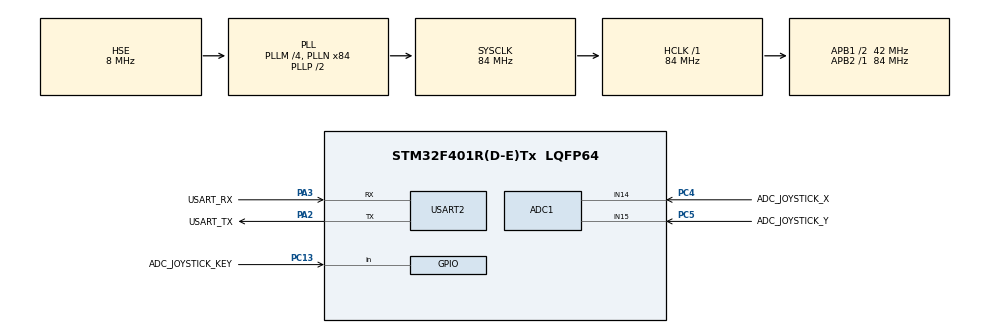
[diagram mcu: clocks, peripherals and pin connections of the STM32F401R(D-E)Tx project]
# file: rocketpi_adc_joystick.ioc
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ADC1.Channel-0\#ChannelRegularConversion=ADC_CHANNEL_14
ADC1.Channel-1\#ChannelRegularConversion=ADC_CHANNEL_15
ADC1.ContinuousConvMode=ENABLE
ADC1.EnableAnalogWatchDog=false
ADC1.InjNumberOfConversion=0
ADC1.NbrOfConversion=2
ADC1.NbrOfConversionFlag=1
ADC1.Rank-0\#ChannelRegularConversion=1
ADC1.Rank-1\#ChannelRegularConversion=2
ADC1.SamplingTime-0\#ChannelRegularConversion=ADC_SAMPLETIME_112CYCLES
ADC1.SamplingTime-1\#ChannelRegularConversion=ADC_SAMPLETIME_112CYCLES
ADC1.ScanConvMode=ENABLE
ADC1.master=1
Mcu.Family=STM32F4
Mcu.Name=STM32F401R(D-E)Tx
Mcu.Package=LQFP64
NVIC.PriorityGroup=NVIC_PRIORITYGROUP_4
PA13.GPIO_Label=TMS
PA13.Mode=Serial_Wire
PA13.Signal=SYS_JTMS-SWDIO
PA14.GPIO_Label=TCK
PA14.Mode=Serial_Wire
PA14.Signal=SYS_JTCK-SWCLK
PA2.GPIO_Label=USART_TX
PA2.GPIO_Mode=GPIO_MODE_AF_PP
PA2.GPIO_PuPd=GPIO_NOPULL
PA2.GPIO_Speed=GPIO_SPEED_FREQ_LOW
PA2.Mode=Asynchronous
PA2.Signal=USART2_TX
PA3.GPIO_Label=USART_RX
PA3.GPIO_Mode=GPIO_MODE_AF_PP
PA3.GPIO_PuPd=GPIO_NOPULL
PA3.GPIO_Speed=GPIO_SPEED_FREQ_LOW
PA3.Mode=Asynchronous
PA3.Signal=USART2_RX
PC13-ANTI_TAMP.GPIO_Label=ADC_JOYSTICK_KEY
PC13-ANTI_TAMP.GPIO_PuPd=GPIO_PULLUP
PC13-ANTI_TAMP.Signal=GPIO_Input
PC4.GPIO_Label=ADC_JOYSTICK_X
PC4.Signal=ADCx_IN14
PC5.GPIO_Label=ADC_JOYSTICK_Y
PC5.Signal=ADCx_IN15
PH0\ -\ OSC_IN.Mode=HSE-External-Oscillator
PH0\ -\ OSC_IN.Signal=RCC_OSC_IN
PH1\ -\ OSC_OUT.Mode=HSE-External-Oscillator
PH1\ -\ OSC_OUT.Signal=RCC_OSC_OUT
ProjectManager.HeapSize=0x800
ProjectManager.StackSize=0x800
ProjectManager.TargetToolchain=MDK-ARM V5.27
RCC.48MHZClocksFreq_Value=24000000
RCC.AHBFreq_Value=84000000
RCC.APB1CLKDivider=RCC_HCLK_DIV2
RCC.APB1Freq_Value=42000000
RCC.APB1TimFreq_Value=84000000
RCC.APB2Freq_Value=84000000
RCC.APB2TimFreq_Value=84000000
RCC.CortexFreq_Value=84000000
RCC.HCLKFreq_Value=84000000
RCC.HSE_VALUE=8000000
RCC.HSI_VALUE=16000000
RCC.LSE_VALUE=32768
RCC.PLLM=4
RCC.PLLN=84
RCC.PLLQ=7
RCC.PLLSourceVirtual=RCC_PLLSOURCE_HSE
RCC.SYSCLKFreq_VALUE=84000000
RCC.SYSCLKSource=RCC_SYSCLKSOURCE_PLLCLK
RCC.VCOOutputFreq_Value=168000000
SH.ADCx_IN14.0=ADC1_IN14,IN14
SH.ADCx_IN15.0=ADC1_IN15,IN15
USART2.VirtualMode=VM_ASYNC
board=NUCLEO-F401RE

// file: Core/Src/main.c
/* USER CODE BEGIN Header */
/**
  ******************************************************************************
  * @file           : main.c
  * @brief          : Main program body
  ******************************************************************************
  * @attention
  *
  * Copyright (c) 2025 STMicroelectronics.
  * All rights reserved.
  *
  * This software is licensed under terms that can be found in the LICENSE file
  * in the root directory of this software component.
  * If no LICENSE file comes with this software, it is provided AS-IS.
  *
  ******************************************************************************
  */
/* USER CODE END Header */
#include "main.h"
#include "adc.h"
#include "usart.h"
#include "gpio.h"

/* USER CODE BEGIN Includes */
#include "driver_adc_joystick_test.h"
/* USER CODE END Includes */

void SystemClock_Config(void);

int main(void)
{

  /* MCU Configuration--------------------------------------------------------*/

  /* Reset of all peripherals, Initializes the Flash interface and the Systick. */
  HAL_Init();

  /* Configure the system clock */
  SystemClock_Config();

  /* Initialize all configured peripherals */
  MX_GPIO_Init();
  MX_USART2_UART_Init();
  MX_ADC1_Init();
  /* USER CODE BEGIN 2 */
	adc_joystick_test_run(0,200);

  /* USER CODE END 2 */

  /* Infinite loop */
  while (1)
  {

  }
}

void SystemClock_Config(void)
{
  RCC_OscInitTypeDef RCC_OscInitStruct = {0};
  RCC_ClkInitTypeDef RCC_ClkInitStruct = {0};

  /** Configure the main internal regulator output voltage
  */
  __HAL_RCC_PWR_CLK_ENABLE();
  __HAL_PWR_VOLTAGESCALING_CONFIG(PWR_REGULATOR_VOLTAGE_SCALE2);

  /** Initializes the RCC Oscillators according to the specified parameters
  * in the RCC_OscInitTypeDef structure.
  */
  RCC_OscInitStruct.OscillatorType = RCC_OSCILLATORTYPE_HSE;
  RCC_OscInitStruct.HSEState = RCC_HSE_ON;
  RCC_OscInitStruct.PLL.PLLState = RCC_PLL_ON;
  RCC_OscInitStruct.PLL.PLLSource = RCC_PLLSOURCE_HSE;
  RCC_OscInitStruct.PLL.PLLM = 4;
  RCC_OscInitStruct.PLL.PLLN = 84;
  RCC_OscInitStruct.PLL.PLLP = RCC_PLLP_DIV2;
  RCC_OscInitStruct.PLL.PLLQ = 7;
  if (HAL_RCC_OscConfig(&RCC_OscInitStruct) != HAL_OK)
  {
    Error_Handler();
  }

  /** Initializes the CPU, AHB and APB buses clocks
  */
  RCC_ClkInitStruct.ClockType = RCC_CLOCKTYPE_HCLK|RCC_CLOCKTYPE_SYSCLK
                              |RCC_CLOCKTYPE_PCLK1|RCC_CLOCKTYPE_PCLK2;
  RCC_ClkInitStruct.SYSCLKSource = RCC_SYSCLKSOURCE_PLLCLK;
  RCC_ClkInitStruct.AHBCLKDivider = RCC_SYSCLK_DIV1;
  RCC_ClkInitStruct.APB1CLKDivider = RCC_HCLK_DIV2;
  RCC_ClkInitStruct.APB2CLKDivider = RCC_HCLK_DIV1;

  if (HAL_RCC_ClockConfig(&RCC_ClkInitStruct, FLASH_LATENCY_2) != HAL_OK)
  {
    Error_Handler();
  }
}

void Error_Handler(void)
{
  __disable_irq();
  while (1)
  {
  }
}
